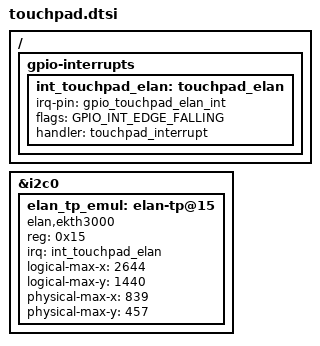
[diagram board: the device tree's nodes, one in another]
/* Copyright 2024 The ChromiumOS Authors
 * Use of this source code is governed by a BSD-style license that can be
 * found in the LICENSE file.
 */

/ {
	gpio-interrupts {
		int_touchpad_elan: touchpad_elan {
			irq-pin = <&gpio_touchpad_elan_int>;
			flags = <GPIO_INT_EDGE_FALLING>;
			handler = "touchpad_interrupt";
		};
	};
};

&i2c0 {
	elan_tp_emul: elan-tp@15 {
		compatible = "elan,ekth3000";
		reg = <0x15>;
		irq = <&int_touchpad_elan>;
		logical-max-x = <2644>;
		logical-max-y = <1440>;
		physical-max-x = <839>;
		physical-max-y = <457>;
	};
};
